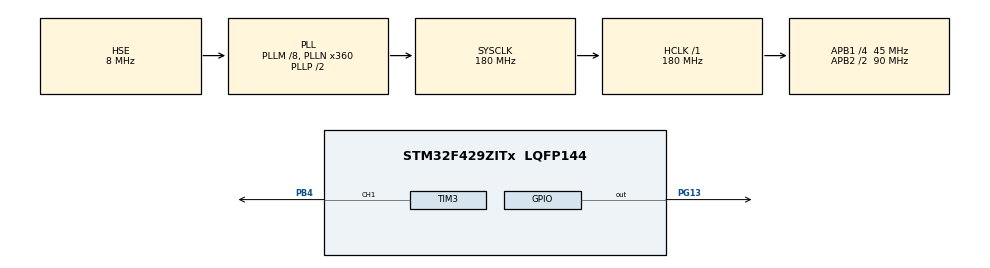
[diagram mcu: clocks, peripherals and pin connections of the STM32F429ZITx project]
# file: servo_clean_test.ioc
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Mcu.Family=STM32F4
Mcu.Name=STM32F429ZITx
Mcu.Package=LQFP144
NVIC.PriorityGroup=NVIC_PRIORITYGROUP_4
PA13.Mode=Serial_Wire
PA13.Signal=SYS_JTMS-SWDIO
PA14.Mode=Serial_Wire
PA14.Signal=SYS_JTCK-SWCLK
PB4.Signal=S_TIM3_CH1
PG13.Signal=GPIO_Output
PH0/OSC_IN.Mode=HSE-External-Oscillator
PH0/OSC_IN.Signal=RCC_OSC_IN
PH1/OSC_OUT.Mode=HSE-External-Oscillator
PH1/OSC_OUT.Signal=RCC_OSC_OUT
ProjectManager.HeapSize=0x200
ProjectManager.StackSize=0x400
ProjectManager.TargetToolchain=STM32CubeIDE
RCC.48MHZClocksFreq_Value=90000000
RCC.AHBFreq_Value=180000000
RCC.APB1CLKDivider=RCC_HCLK_DIV4
RCC.APB1Freq_Value=45000000
RCC.APB1TimFreq_Value=90000000
RCC.APB2CLKDivider=RCC_HCLK_DIV2
RCC.APB2Freq_Value=90000000
RCC.APB2TimFreq_Value=180000000
RCC.CortexFreq_Value=180000000
RCC.HCLKFreq_Value=180000000
RCC.HSE_VALUE=8000000
RCC.HSI_VALUE=16000000
RCC.LSE_VALUE=32768
RCC.PLLM=8
RCC.PLLN=360
RCC.PLLSourceVirtual=RCC_PLLSOURCE_HSE
RCC.SYSCLKFreq_VALUE=180000000
RCC.SYSCLKSource=RCC_SYSCLKSOURCE_PLLCLK
RCC.VCOOutputFreq_Value=360000000
SH.S_TIM3_CH1.0=TIM3_CH1,PWM Generation1 CH1
TIM3.Channel-PWM\ Generation1\ CH1=TIM_CHANNEL_1
TIM3.Period=19999
TIM3.Prescaler=89
TIM3.Pulse-PWM\ Generation1\ CH1=1500
VP_TIM3_VS_ClockSourceINT.Mode=Internal
board=custom

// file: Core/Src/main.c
/* USER CODE BEGIN Header */
/**
  ******************************************************************************
  * @file           : main.c
  * @brief          : Main program body
  ******************************************************************************
  * @attention
  *
  * Copyright (c) 2026 STMicroelectronics.
  * All rights reserved.
  *
  * This software is licensed under terms that can be found in the LICENSE file
  * in the root directory of this software component.
  * If no LICENSE file comes with this software, it is provided AS-IS.
  *
  ******************************************************************************
  */
/* USER CODE END Header */
#include "main.h"

TIM_HandleTypeDef htim3;

void SystemClock_Config(void);
static void MX_GPIO_Init(void);
static void MX_TIM3_Init(void);

/* USER CODE BEGIN 0 */

#define SERVO_MIN_US     1000U
#define SERVO_MID_US     1500U
#define SERVO_MAX_US     2000U

static void Servo_SetPulseUs(uint16_t pulse_us)
{
    if (pulse_us < SERVO_MIN_US)
    {
        pulse_us = SERVO_MIN_US;
    }

    if (pulse_us > SERVO_MAX_US)
    {
        pulse_us = SERVO_MAX_US;
    }

    __HAL_TIM_SET_COMPARE(&htim3, TIM_CHANNEL_1, pulse_us);
}

static void Servo_SetAngle(uint16_t angle_deg)
{
    uint32_t pulse_us;

    if (angle_deg > 180U)
    {
        angle_deg = 180U;
    }

    pulse_us = SERVO_MIN_US +
               ((uint32_t)angle_deg * (SERVO_MAX_US - SERVO_MIN_US)) / 180U;

    Servo_SetPulseUs((uint16_t)pulse_us);
}

/* USER CODE END 0 */

int main(void)
{

  /* MCU Configuration--------------------------------------------------------*/

  /* Reset of all peripherals, Initializes the Flash interface and the Systick. */
  HAL_Init();

  /* Configure the system clock */
  SystemClock_Config();

  /* Initialize all configured peripherals */
  MX_GPIO_Init();
  MX_TIM3_Init();
  /* USER CODE BEGIN 2 */

  HAL_TIM_PWM_Start(&htim3, TIM_CHANNEL_1);

//  Servo_SetAngle(90U);
//  HAL_Delay(1000);

  /* USER CODE END 2 */

  /* Infinite loop */
  while (1)
  {

    /* USER CODE BEGIN 3 */

	  /* Quét từ trái sang phải */
	  for (uint16_t pulse = 900U; pulse <= 6500U; pulse += 30U)
	  {
	      __HAL_TIM_SET_COMPARE(&htim3, TIM_CHANNEL_1, pulse);
	      HAL_GPIO_TogglePin(GPIOG, GPIO_PIN_13);
	      HAL_Delay(100);
	  }

	  HAL_Delay(1000);

	  /* Quét từ phải sang trái */
	  for (int16_t pulse = 6500; pulse >= 900; pulse -= 30)
	  {
	      __HAL_TIM_SET_COMPARE(&htim3, TIM_CHANNEL_1, (uint16_t)pulse);
	      HAL_GPIO_TogglePin(GPIOG, GPIO_PIN_13);
	      HAL_Delay(100);
	  }

	  HAL_Delay(1000);
  }
  /* USER CODE END 3 */
}

void SystemClock_Config(void)
{
  RCC_OscInitTypeDef RCC_OscInitStruct = {0};
  RCC_ClkInitTypeDef RCC_ClkInitStruct = {0};

  /** Configure the main internal regulator output voltage
  */
  __HAL_RCC_PWR_CLK_ENABLE();
  __HAL_PWR_VOLTAGESCALING_CONFIG(PWR_REGULATOR_VOLTAGE_SCALE1);

  /** Initializes the RCC Oscillators according to the specified parameters
  * in the RCC_OscInitTypeDef structure.
  */
  RCC_OscInitStruct.OscillatorType = RCC_OSCILLATORTYPE_HSE;
  RCC_OscInitStruct.HSEState = RCC_HSE_ON;
  RCC_OscInitStruct.PLL.PLLState = RCC_PLL_ON;
  RCC_OscInitStruct.PLL.PLLSource = RCC_PLLSOURCE_HSE;
  RCC_OscInitStruct.PLL.PLLM = 8;
  RCC_OscInitStruct.PLL.PLLN = 360;
  RCC_OscInitStruct.PLL.PLLP = RCC_PLLP_DIV2;
  RCC_OscInitStruct.PLL.PLLQ = 4;
  if (HAL_RCC_OscConfig(&RCC_OscInitStruct) != HAL_OK)
  {
    Error_Handler();
  }

  /** Activate the Over-Drive mode
  */
  if (HAL_PWREx_EnableOverDrive() != HAL_OK)
  {
    Error_Handler();
  }

  /** Initializes the CPU, AHB and APB buses clocks
  */
  RCC_ClkInitStruct.ClockType = RCC_CLOCKTYPE_HCLK|RCC_CLOCKTYPE_SYSCLK
                              |RCC_CLOCKTYPE_PCLK1|RCC_CLOCKTYPE_PCLK2;
  RCC_ClkInitStruct.SYSCLKSource = RCC_SYSCLKSOURCE_PLLCLK;
  RCC_ClkInitStruct.AHBCLKDivider = RCC_SYSCLK_DIV1;
  RCC_ClkInitStruct.APB1CLKDivider = RCC_HCLK_DIV4;
  RCC_ClkInitStruct.APB2CLKDivider = RCC_HCLK_DIV2;

  if (HAL_RCC_ClockConfig(&RCC_ClkInitStruct, FLASH_LATENCY_5) != HAL_OK)
  {
    Error_Handler();
  }
}

static void MX_TIM3_Init(void)
{

  TIM_ClockConfigTypeDef sClockSourceConfig = {0};
  TIM_MasterConfigTypeDef sMasterConfig = {0};
  TIM_OC_InitTypeDef sConfigOC = {0};

  htim3.Instance = TIM3;
  htim3.Init.Prescaler = 89;
  htim3.Init.CounterMode = TIM_COUNTERMODE_UP;
  htim3.Init.Period = 19999;
  htim3.Init.ClockDivision = TIM_CLOCKDIVISION_DIV1;
  htim3.Init.AutoReloadPreload = TIM_AUTORELOAD_PRELOAD_DISABLE;
  if (HAL_TIM_Base_Init(&htim3) != HAL_OK)
  {
    Error_Handler();
  }
  sClockSourceConfig.ClockSource = TIM_CLOCKSOURCE_INTERNAL;
  if (HAL_TIM_ConfigClockSource(&htim3, &sClockSourceConfig) != HAL_OK)
  {
    Error_Handler();
  }
  if (HAL_TIM_PWM_Init(&htim3) != HAL_OK)
  {
    Error_Handler();
  }
  sMasterConfig.MasterOutputTrigger = TIM_TRGO_RESET;
  sMasterConfig.MasterSlaveMode = TIM_MASTERSLAVEMODE_DISABLE;
  if (HAL_TIMEx_MasterConfigSynchronization(&htim3, &sMasterConfig) != HAL_OK)
  {
    Error_Handler();
  }
  sConfigOC.OCMode = TIM_OCMODE_PWM1;
  sConfigOC.Pulse = 1500;
  sConfigOC.OCPolarity = TIM_OCPOLARITY_HIGH;
  sConfigOC.OCFastMode = TIM_OCFAST_DISABLE;
  if (HAL_TIM_PWM_ConfigChannel(&htim3, &sConfigOC, TIM_CHANNEL_1) != HAL_OK)
  {
    Error_Handler();
  }
  HAL_TIM_MspPostInit(&htim3);

}

static void MX_GPIO_Init(void)
{
  GPIO_InitTypeDef GPIO_InitStruct = {0};

  /* GPIO Ports Clock Enable */
  __HAL_RCC_GPIOH_CLK_ENABLE();
  __HAL_RCC_GPIOA_CLK_ENABLE();
  __HAL_RCC_GPIOG_CLK_ENABLE();
  __HAL_RCC_GPIOB_CLK_ENABLE();

  /*Configure GPIO pin Output Level */
  HAL_GPIO_WritePin(GPIOG, GPIO_PIN_13, GPIO_PIN_RESET);

  /*Configure GPIO pin : PG13 */
  GPIO_InitStruct.Pin = GPIO_PIN_13;
  GPIO_InitStruct.Mode = GPIO_MODE_OUTPUT_PP;
  GPIO_InitStruct.Pull = GPIO_NOPULL;
  GPIO_InitStruct.Speed = GPIO_SPEED_FREQ_LOW;
  HAL_GPIO_Init(GPIOG, &GPIO_InitStruct);

}

void Error_Handler(void)
{
  __disable_irq();
  while (1)
  {
  }
}
